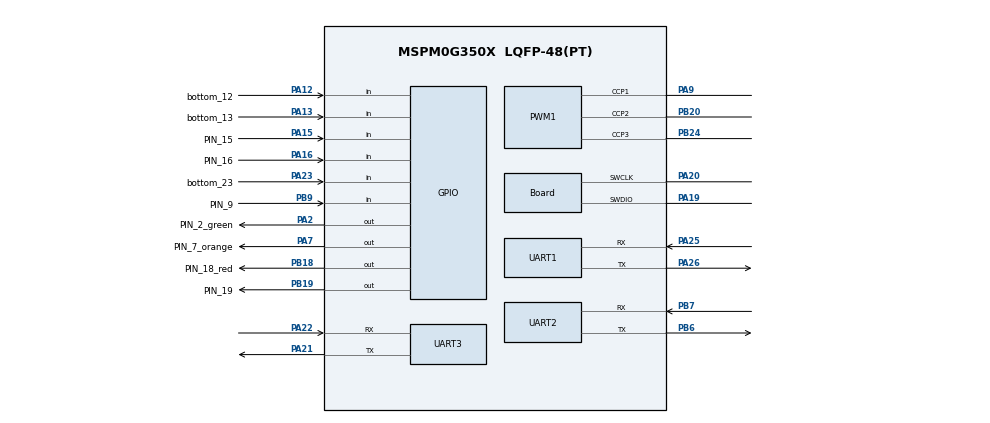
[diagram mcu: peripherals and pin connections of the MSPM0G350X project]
/**
 * @cliArgs --device "MSPM0G350X" --part "Default" --package "LQFP-48(PT)" --product "mspm0_sdk@2.04.00.06"
 * @versions {"tool":"1.22.0+3893"}
 */

/**
 * Import the modules used in this configuration.
 */
const GPIO   = scripting.addModule("/ti/driverlib/GPIO", {}, false);
const GPIO1  = GPIO.addInstance();
const GPIO2  = GPIO.addInstance();
const GPIO3  = GPIO.addInstance();
const GPIO4  = GPIO.addInstance();
const GPIO5  = GPIO.addInstance();
const GPIO6  = GPIO.addInstance();
const GPIO7  = GPIO.addInstance();
const GPIO8  = GPIO.addInstance();
const PWM    = scripting.addModule("/ti/driverlib/PWM", {}, false);
const PWM1   = PWM.addInstance();
const SYSCTL = scripting.addModule("/ti/driverlib/SYSCTL");
const TIMER  = scripting.addModule("/ti/driverlib/TIMER", {}, false);
const TIMER1 = TIMER.addInstance();
const UART   = scripting.addModule("/ti/driverlib/UART", {}, false);
const UART1  = UART.addInstance();
const UART2  = UART.addInstance();
const UART3  = UART.addInstance();

/**
 * Write custom configuration values to the imported modules.
 */
const divider7       = system.clockTree["PLL_PDIV"];
divider7.divideValue = 8;

const divider9       = system.clockTree["UDIV"];
divider9.divideValue = 2;

const multiplier2         = system.clockTree["PLL_QDIV"];
multiplier2.multiplyValue = 40;

const mux8       = system.clockTree["HSCLKMUX"];
mux8.inputSelect = "HSCLKMUX_SYSPLL0";

GPIO1.port                                = "PORTA";
GPIO1.$name                               = "bottoms";
GPIO1.associatedPins.create(4);
GPIO1.associatedPins[0].assignedPin       = "14";
GPIO1.associatedPins[0].direction         = "INPUT";
GPIO1.associatedPins[0].interruptEn       = true;
GPIO1.associatedPins[0].interruptPriority = "0";
GPIO1.associatedPins[0].$name             = "bottom_14";
GPIO1.associatedPins[0].internalResistor  = "PULL_UP";
GPIO1.associatedPins[0].polarity          = "FALL";
GPIO1.associatedPins[1].$name             = "bottom_13";
GPIO1.associatedPins[1].direction         = "INPUT";
GPIO1.associatedPins[1].assignedPin       = "13";
GPIO1.associatedPins[1].interruptEn       = true;
GPIO1.associatedPins[1].interruptPriority = "0";
GPIO1.associatedPins[1].internalResistor  = "PULL_UP";
GPIO1.associatedPins[1].polarity          = "FALL";
GPIO1.associatedPins[1].pin.$assign       = "PA13";
GPIO1.associatedPins[2].$name             = "bottom_12";
GPIO1.associatedPins[2].assignedPin       = "12";
GPIO1.associatedPins[2].direction         = "INPUT";
GPIO1.associatedPins[2].interruptEn       = true;
GPIO1.associatedPins[2].interruptPriority = "0";
GPIO1.associatedPins[2].internalResistor  = "PULL_UP";
GPIO1.associatedPins[2].polarity          = "RISE";
GPIO1.associatedPins[2].pin.$assign       = "PA12";
GPIO1.associatedPins[3].$name             = "bottom_23";
GPIO1.associatedPins[3].direction         = "INPUT";
GPIO1.associatedPins[3].assignedPin       = "23";
GPIO1.associatedPins[3].interruptEn       = true;
GPIO1.associatedPins[3].interruptPriority = "0";
GPIO1.associatedPins[3].internalResistor  = "PULL_UP";
GPIO1.associatedPins[3].polarity          = "FALL";
GPIO1.associatedPins[3].pin.$assign       = "PA23";

const Board                       = scripting.addModule("/ti/driverlib/Board", {}, false);
Board.peripheral.$assign          = "DEBUGSS";
Board.peripheral.swclkPin.$assign = "PA20";
Board.peripheral.swdioPin.$assign = "PA19";

GPIO2.$name                               = "L1_Encoder_B";
GPIO2.port                                = "PORTA";
GPIO2.associatedPins[0].$name             = "PIN_16";
GPIO2.associatedPins[0].direction         = "INPUT";
GPIO2.associatedPins[0].interruptPriority = "0";
GPIO2.associatedPins[0].polarity          = "RISE";
GPIO2.associatedPins[0].pin.$assign       = "PA16";

GPIO3.$name                               = "L2_Encoder_A";
GPIO3.port                                = "PORTB";
GPIO3.associatedPins[0].$name             = "PIN_8";
GPIO3.associatedPins[0].direction         = "INPUT";
GPIO3.associatedPins[0].interruptEn       = true;
GPIO3.associatedPins[0].polarity          = "RISE";
GPIO3.associatedPins[0].interruptPriority = "2";

GPIO4.$name                               = "L2_Encoder_B";
GPIO4.port                                = "PORTB";
GPIO4.associatedPins[0].$name             = "PIN_9";
GPIO4.associatedPins[0].direction         = "INPUT";
GPIO4.associatedPins[0].interruptPriority = "0";
GPIO4.associatedPins[0].polarity          = "RISE";
GPIO4.associatedPins[0].pin.$assign       = "PB9";

GPIO5.$name                               = "L1_Encoder_A";
GPIO5.port                                = "PORTA";
GPIO5.associatedPins[0].$name             = "PIN_15";
GPIO5.associatedPins[0].direction         = "INPUT";
GPIO5.associatedPins[0].interruptEn       = true;
GPIO5.associatedPins[0].interruptPriority = "2";
GPIO5.associatedPins[0].polarity          = "RISE";
GPIO5.associatedPins[0].pin.$assign       = "PA15";

GPIO6.$name                              = "led";
GPIO6.port                               = "PORTB";
GPIO6.associatedPins[0].initialValue     = "SET";
GPIO6.associatedPins[0].internalResistor = "PULL_UP";
GPIO6.associatedPins[0].$name            = "PIN_18_red";
GPIO6.associatedPins[0].pin.$assign      = "PB18";

GPIO7.$name                              = "buzzer";
GPIO7.port                               = "PORTB";
GPIO7.associatedPins[0].$name            = "PIN_19";
GPIO7.associatedPins[0].internalResistor = "PULL_DOWN";
GPIO7.associatedPins[0].pin.$assign      = "PB19";

GPIO8.$name                          = "led2";
GPIO8.port                           = "PORTA";
GPIO8.associatedPins.create(2);
GPIO8.associatedPins[0].$name        = "PIN_7_orange";
GPIO8.associatedPins[0].initialValue = "SET";
GPIO8.associatedPins[0].pin.$assign  = "PA7";
GPIO8.associatedPins[1].$name        = "PIN_2_green";
GPIO8.associatedPins[1].initialValue = "SET";
GPIO8.associatedPins[1].pin.$assign  = "PA2";

PWM1.$name                              = "PWM_TIMA0";
PWM1.ccIndex                            = [0,1,2,3];
PWM1.timerStartTimer                    = true;
PWM1.pwmMode                            = "EDGE_ALIGN_UP";
PWM1.timerCount                         = 8000;
PWM1.peripheral.ccp1Pin.$assign         = "PA9";
PWM1.peripheral.ccp2Pin.$assign         = "PB20";
PWM1.peripheral.ccp3Pin.$assign         = "PB24";
PWM1.PWM_CHANNEL_0.$name                = "ti_driverlib_pwm_PWMTimerCC2";
PWM1.PWM_CHANNEL_1.$name                = "ti_driverlib_pwm_PWMTimerCC3";
PWM1.ccp0PinConfig.direction            = scripting.forceWrite("OUTPUT");
PWM1.ccp0PinConfig.hideOutputInversion  = scripting.forceWrite(false);
PWM1.ccp0PinConfig.onlyInternalResistor = scripting.forceWrite(false);
PWM1.ccp0PinConfig.passedPeripheralType = scripting.forceWrite("Digital");
PWM1.ccp0PinConfig.$name                = "ti_driverlib_gpio_GPIOPinGeneric10";
PWM1.ccp1PinConfig.direction            = scripting.forceWrite("OUTPUT");
PWM1.ccp1PinConfig.hideOutputInversion  = scripting.forceWrite(false);
PWM1.ccp1PinConfig.onlyInternalResistor = scripting.forceWrite(false);
PWM1.ccp1PinConfig.passedPeripheralType = scripting.forceWrite("Digital");
PWM1.ccp1PinConfig.$name                = "ti_driverlib_gpio_GPIOPinGeneric11";
PWM1.PWM_CHANNEL_2.$name                = "ti_driverlib_pwm_PWMTimerCC4";
PWM1.PWM_CHANNEL_3.$name                = "ti_driverlib_pwm_PWMTimerCC5";
PWM1.ccp2PinConfig.$name                = "ti_driverlib_gpio_GPIOPinGeneric12";
PWM1.ccp3PinConfig.$name                = "ti_driverlib_gpio_GPIOPinGeneric13";

SYSCTL.forceDefaultClkConfig = true;
SYSCTL.clockTreeEn           = true;

TIMER1.$name             = "TIMER_0";
TIMER1.timerClkPrescale  = 32;
TIMER1.timerMode         = "PERIODIC_UP";
TIMER1.timerPeriod       = "1 ms";
TIMER1.timerStartTimer   = true;
TIMER1.interruptPriority = "0";
TIMER1.interrupts        = ["LOAD"];

UART1.$name                                = "TLY";
UART1.targetBaudRate                       = 115200;
UART1.interruptPriority                    = "0";
UART1.enableFIFO                           = true;
UART1.rxFifoThreshold                      = "DL_UART_RX_FIFO_LEVEL_ONE_ENTRY";
UART1.txFifoThreshold                      = "DL_UART_TX_FIFO_LEVEL_ONE_ENTRY";
UART1.enabledDMARXTriggers                 = "DL_UART_DMA_INTERRUPT_RX";
UART1.enabledInterrupts                    = ["DMA_DONE_RX","TX"];
UART1.peripheral.$assign                   = "UART3";
UART1.peripheral.rxPin.$assign             = "PA25";
UART1.peripheral.txPin.$assign             = "PA26";
UART1.txPinConfig.direction                = scripting.forceWrite("OUTPUT");
UART1.txPinConfig.hideOutputInversion      = scripting.forceWrite(false);
UART1.txPinConfig.onlyInternalResistor     = scripting.forceWrite(false);
UART1.txPinConfig.passedPeripheralType     = scripting.forceWrite("Digital");
UART1.txPinConfig.$name                    = "ti_driverlib_gpio_GPIOPinGeneric0";
UART1.rxPinConfig.hideOutputInversion      = scripting.forceWrite(false);
UART1.rxPinConfig.onlyInternalResistor     = scripting.forceWrite(false);
UART1.rxPinConfig.passedPeripheralType     = scripting.forceWrite("Digital");
UART1.rxPinConfig.$name                    = "ti_driverlib_gpio_GPIOPinGeneric1";
UART1.DMA_CHANNEL_RX.$name                 = "DMA_CH0";
UART1.DMA_CHANNEL_RX.addressMode           = "f2b";
UART1.DMA_CHANNEL_RX.srcLength             = "BYTE";
UART1.DMA_CHANNEL_RX.dstLength             = "BYTE";
UART1.DMA_CHANNEL_RX.configureTransferSize = true;
UART1.DMA_CHANNEL_RX.transferMode          = "FULL_CH_REPEAT_SINGLE";

UART2.$name                            = "BLE";
UART2.interruptPriority                = "0";
UART2.enabledInterrupts                = ["RX","TX"];
UART2.peripheral.$assign               = "UART1";
UART2.peripheral.rxPin.$assign         = "PB7";
UART2.peripheral.txPin.$assign         = "PB6";
UART2.txPinConfig.direction            = scripting.forceWrite("OUTPUT");
UART2.txPinConfig.hideOutputInversion  = scripting.forceWrite(false);
UART2.txPinConfig.onlyInternalResistor = scripting.forceWrite(false);
UART2.txPinConfig.passedPeripheralType = scripting.forceWrite("Digital");
UART2.txPinConfig.$name                = "ti_driverlib_gpio_GPIOPinGeneric2";
UART2.rxPinConfig.hideOutputInversion  = scripting.forceWrite(false);
UART2.rxPinConfig.onlyInternalResistor = scripting.forceWrite(false);
UART2.rxPinConfig.passedPeripheralType = scripting.forceWrite("Digital");
UART2.rxPinConfig.$name                = "ti_driverlib_gpio_GPIOPinGeneric3";

UART3.$name                                = "MAIX";
UART3.targetBaudRate                       = 115200;
UART3.interruptPriority                    = "0";
UART3.enableFIFO                           = true;
UART3.rxFifoThreshold                      = "DL_UART_RX_FIFO_LEVEL_ONE_ENTRY";
UART3.txFifoThreshold                      = "DL_UART_TX_FIFO_LEVEL_ONE_ENTRY";
UART3.enabledDMARXTriggers                 = "DL_UART_DMA_INTERRUPT_RX";
UART3.enabledInterrupts                    = ["DMA_DONE_RX"];
UART3.peripheral.$assign                   = "UART2";
UART3.peripheral.rxPin.$assign             = "PA22";
UART3.peripheral.txPin.$assign             = "PA21";
UART3.txPinConfig.direction                = scripting.forceWrite("OUTPUT");
UART3.txPinConfig.hideOutputInversion      = scripting.forceWrite(false);
UART3.txPinConfig.onlyInternalResistor     = scripting.forceWrite(false);
UART3.txPinConfig.passedPeripheralType     = scripting.forceWrite("Digital");
UART3.txPinConfig.$name                    = "ti_driverlib_gpio_GPIOPinGeneric4";
UART3.rxPinConfig.hideOutputInversion      = scripting.forceWrite(false);
UART3.rxPinConfig.onlyInternalResistor     = scripting.forceWrite(false);
UART3.rxPinConfig.passedPeripheralType     = scripting.forceWrite("Digital");
UART3.rxPinConfig.$name                    = "ti_driverlib_gpio_GPIOPinGeneric5";
UART3.DMA_CHANNEL_RX.$name                 = "DMA_CH1";
UART3.DMA_CHANNEL_RX.srcLength             = "BYTE";
UART3.DMA_CHANNEL_RX.dstLength             = "BYTE";
UART3.DMA_CHANNEL_RX.configureTransferSize = true;
UART3.DMA_CHANNEL_RX.transferMode          = "FULL_CH_REPEAT_SINGLE";
UART3.DMA_CHANNEL_RX.addressMode           = "f2b";
UART3.DMA_CHANNEL_RX.peripheral.$assign    = "DMA_CH1";

const ProjectConfig              = scripting.addModule("/ti/project_config/ProjectConfig", {}, false);
ProjectConfig.migrationCondition = true;

/**
 * Pinmux solution for unlocked pins/peripherals. This ensures that minor changes to the automatic solver in a future
 * version of the tool will not impact the pinmux you originally saw.  These lines can be completely deleted in order to
 * re-solve from scratch.
 */
GPIO1.associatedPins[0].pin.$suggestSolution     = "PA14";
GPIO3.associatedPins[0].pin.$suggestSolution     = "PB2";
PWM1.peripheral.$suggestSolution                 = "TIMA0";
PWM1.peripheral.ccp0Pin.$suggestSolution         = "PA0";
TIMER1.peripheral.$suggestSolution               = "TIMA1";
UART1.DMA_CHANNEL_RX.peripheral.$suggestSolution = "DMA_CH0";
